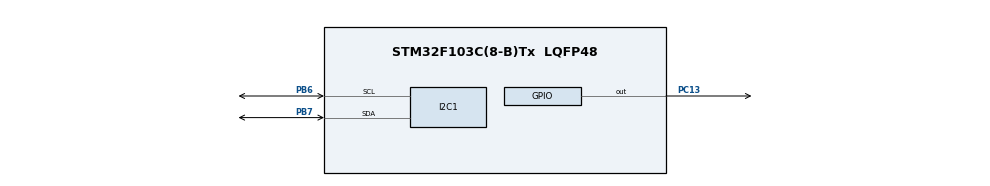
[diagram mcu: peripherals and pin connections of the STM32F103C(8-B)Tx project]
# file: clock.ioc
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Mcu.Family=STM32F1
Mcu.Name=STM32F103C(8-B)Tx
Mcu.Package=LQFP48
NVIC.PriorityGroup=NVIC_PRIORITYGROUP_4
PA13.Mode=Serial_Wire
PA13.Signal=SYS_JTMS-SWDIO
PA14.Mode=Serial_Wire
PA14.Signal=SYS_JTCK-SWCLK
PB6.Mode=I2C
PB6.Signal=I2C1_SCL
PB7.Mode=I2C
PB7.Signal=I2C1_SDA
PC13-TAMPER-RTC.Signal=GPIO_Output
PC14-OSC32_IN.Mode=LSE-External-Oscillator
PC14-OSC32_IN.Signal=RCC_OSC32_IN
PC15-OSC32_OUT.Mode=LSE-External-Oscillator
PC15-OSC32_OUT.Signal=RCC_OSC32_OUT
ProjectManager.HeapSize=0x200
ProjectManager.StackSize=0x400
ProjectManager.TargetToolchain=STM32CubeIDE
RCC.APB1Freq_Value=8000000
RCC.APB2Freq_Value=8000000
RCC.RTCClockSelection=RCC_RTCCLKSOURCE_LSE
RTC.Date=18
RTC.Hours=14
RTC.Minutes=12
RTC.Month=RTC_MONTH_MARCH
RTC.WeekDay=RTC_WEEKDAY_WEDNESDAY
VP_RTC_VS_RTC_Activate.Mode=RTC_Enabled
VP_RTC_VS_RTC_Calendar.Mode=RTC_Calendar
board=custom

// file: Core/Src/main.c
/* USER CODE BEGIN Header */
/**
  ******************************************************************************
  * @file           : main.c
  * @brief          : Main program body
  ******************************************************************************
  * @attention
  *
  * Copyright (c) 2026 STMicroelectronics.
  * All rights reserved.
  *
  * This software is licensed under terms that can be found in the LICENSE file
  * in the root directory of this software component.
  * If no LICENSE file comes with this software, it is provided AS-IS.
  *
  ******************************************************************************
  */
/* USER CODE END Header */
#include "main.h"
#include "i2c.h"
#include "rtc.h"
#include "gpio.h"

/* USER CODE BEGIN Includes */
#include "ssd1306.h"
#include "fonts.h"
#include <stdio.h> // This is for formatting the time string
/* USER CODE END Includes */

/* USER CODE BEGIN PV */
RTC_TimeTypeDef sTime;
RTC_DateTypeDef sDate;
char time_buffer[20]; // To hold the text "HH:MM:SS"
/* USER CODE END PV */

void SystemClock_Config(void);

int main(void)
{

  /* MCU Configuration--------------------------------------------------------*/

  /* Reset of all peripherals, Initializes the Flash interface and the Systick. */
  HAL_Init();

  /* Configure the system clock */
  SystemClock_Config();

  /* Initialize all configured peripherals */
  MX_GPIO_Init();
  MX_RTC_Init();
  MX_I2C1_Init();
  /* USER CODE BEGIN 2 */
  ssd1306_Init(); // Turn on the OLED hardware
  ssd1306_Fill(Black); // Clear any old junk off the screen
  ssd1306_SetCursor(20, 0); // Position the text
  ssd1306_WriteString("DIGITAL CLOCK", Font_7x10);
  ssd1306_UpdateScreen(); // Actually push the data to the screen
  HAL_Delay(1000); // Wait a second so you can see the title
  /* USER CODE END 2 */

  /* Infinite loop */
  /* USER CODE BEGIN WHILE */
  while (1)
  {/* 1. Get current time and date from RTC */
	  HAL_RTC_GetTime(&hrtc, &sTime, RTC_FORMAT_BIN);
	  HAL_RTC_GetDate(&hrtc, &sDate, RTC_FORMAT_BIN); // MUST be called after GetTime!

	  /* 2. Format the time into a string */
	  sprintf(time_buffer, "%02d:%02d:%02d", sTime.Hours, sTime.Minutes, sTime.Seconds);

	  /* 3. Update the OLED Display */
	  ssd1306_SetCursor(20, 30); // Move below the title
	  ssd1306_WriteString(time_buffer, Font_11x18); // Large font for visibility
	  ssd1306_UpdateScreen();

	  HAL_Delay(500); // Refresh twice a second for a smooth look
    /* USER CODE END WHILE */

  }
}

void SystemClock_Config(void)
{
  RCC_OscInitTypeDef RCC_OscInitStruct = {0};
  RCC_ClkInitTypeDef RCC_ClkInitStruct = {0};
  RCC_PeriphCLKInitTypeDef PeriphClkInit = {0};

  /** Initializes the RCC Oscillators according to the specified parameters
  * in the RCC_OscInitTypeDef structure.
  */
  RCC_OscInitStruct.OscillatorType = RCC_OSCILLATORTYPE_HSI|RCC_OSCILLATORTYPE_LSE;
  RCC_OscInitStruct.LSEState = RCC_LSE_ON;
  RCC_OscInitStruct.HSIState = RCC_HSI_ON;
  RCC_OscInitStruct.HSICalibrationValue = RCC_HSICALIBRATION_DEFAULT;
  RCC_OscInitStruct.PLL.PLLState = RCC_PLL_NONE;
  if (HAL_RCC_OscConfig(&RCC_OscInitStruct) != HAL_OK)
  {
    Error_Handler();
  }

  /** Initializes the CPU, AHB and APB buses clocks
  */
  RCC_ClkInitStruct.ClockType = RCC_CLOCKTYPE_HCLK|RCC_CLOCKTYPE_SYSCLK
                              |RCC_CLOCKTYPE_PCLK1|RCC_CLOCKTYPE_PCLK2;
  RCC_ClkInitStruct.SYSCLKSource = RCC_SYSCLKSOURCE_HSI;
  RCC_ClkInitStruct.AHBCLKDivider = RCC_SYSCLK_DIV1;
  RCC_ClkInitStruct.APB1CLKDivider = RCC_HCLK_DIV1;
  RCC_ClkInitStruct.APB2CLKDivider = RCC_HCLK_DIV1;

  if (HAL_RCC_ClockConfig(&RCC_ClkInitStruct, FLASH_LATENCY_0) != HAL_OK)
  {
    Error_Handler();
  }
  PeriphClkInit.PeriphClockSelection = RCC_PERIPHCLK_RTC;
  PeriphClkInit.RTCClockSelection = RCC_RTCCLKSOURCE_LSE;
  if (HAL_RCCEx_PeriphCLKConfig(&PeriphClkInit) != HAL_OK)
  {
    Error_Handler();
  }
}

void Error_Handler(void)
{
  __disable_irq();
  while (1)
  {
  }
}
